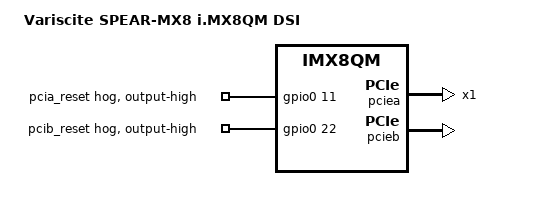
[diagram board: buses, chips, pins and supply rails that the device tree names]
/*
 * Copyright 2019 Variscite Ltd.
 *
 * This program is free software; you can redistribute it and/or
 * modify it under the terms of the GNU General Public License
 * as published by the Free Software Foundation; either version 2
 * of the License, or (at your option) any later version.
 *
 * This program is distributed in the hope that it will be useful,
 * but WITHOUT ANY WARRANTY; without even the implied warranty of
 * MERCHANTABILITY or FITNESS FOR A PARTICULAR PURPOSE.  See the
 * GNU General Public License for more details.
 */

#include "fsl-imx8qm-var-spear-common.dtsi"
#include "fsl-imx8qm-var-spear-dsi.dtsi"

/ {
	model = "Variscite SPEAR-MX8 i.MX8QM DSI";
};

&pciea {
	hsio-cfg = <PCIEAX2PCIEBX1>;
	fsl,max-link-speed = <1>;
	num-lanes = <1>;
	status = "okay";
};

&pcieb {
	ext_osc = <1>;
	status = "okay";
	hsio-cfg = <PCIEAX2PCIEBX1>;
	fsl,max-link-speed = <1>;
};

&gpio0 {
	pcia_reset {
		gpio-hog;
		gpios = <11 0>;
		output-high;
		line-name = "pcia_reset";
	};

	pcib_reset {
		gpio-hog;
		gpios = <22 0>;
		output-high;
		line-name = "pcib_reset";
	};
};

&sata
{
	status = "disabled";
};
